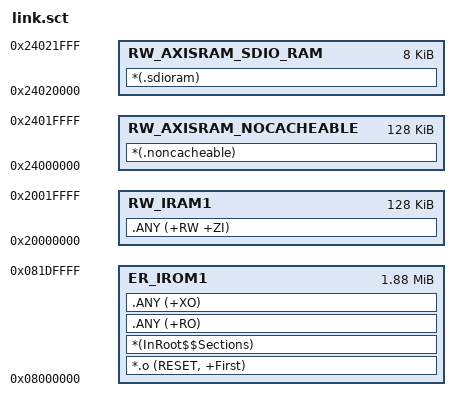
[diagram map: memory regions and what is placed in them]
; *************************************************************
; *** Scatter-Loading Description File generated by uVision ***
; *************************************************************

LR_IROM1 0x08000000 0x001E0000  {    ; load region size_region
  ER_IROM1 0x08000000 0x001E0000  {  ; load address = execution address
   *.o (RESET, +First)
   *(InRoot$$Sections)
   .ANY (+RO)
   .ANY (+XO)
  }
  
  RW_IRAM1 0x20000000 0x00020000  {  ; DTCM 128K
   .ANY (+RW +ZI)
  }
  
  RW_AXISRAM_NOCACHEABLE 0x24000000 0x00020000  {  ; RW data
   *(.noncacheable)
  }

  RW_AXISRAM_SDIO_RAM 0x24020000 0x00002000  {  ; RW data
   *(.sdioram)
  }
}
